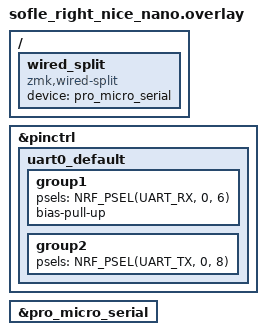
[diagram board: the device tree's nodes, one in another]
#include <zephyr/dt-bindings/pinctrl/nrf-pinctrl.h>

&pinctrl {
	uart0_default: uart0_default {
		group1 {
			psels = <NRF_PSEL(UART_RX, 0, 6)>;
			bias-pull-up;
		};
		group2 {
			psels = <NRF_PSEL(UART_TX, 0, 8)>;
		};
	};
};

&pro_micro_serial {
	status = "okay";
};

/ {
	wired_split {
		compatible = "zmk,wired-split";
		device = <&pro_micro_serial>;
	};
};
